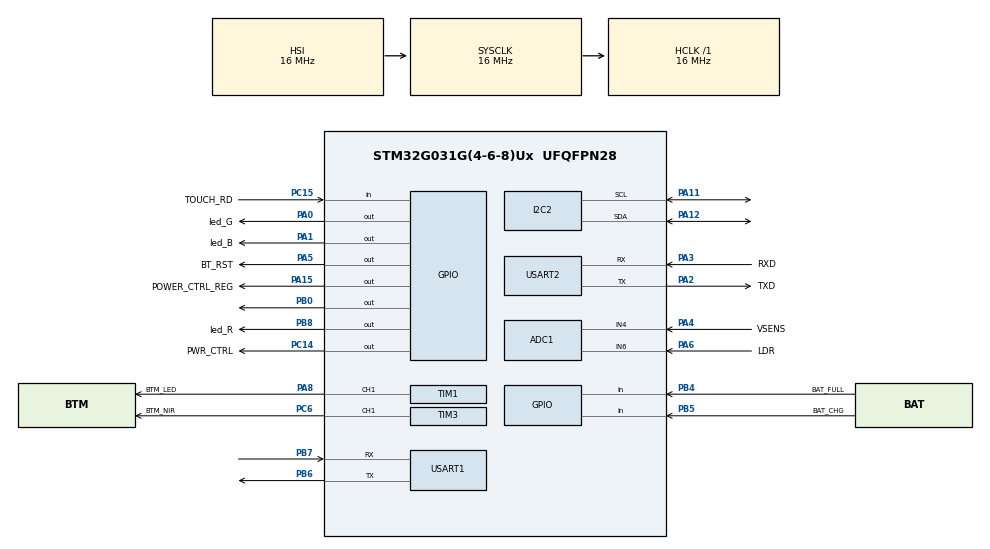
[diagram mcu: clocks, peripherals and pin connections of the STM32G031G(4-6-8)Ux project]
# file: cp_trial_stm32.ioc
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ADC1.Channel-1\#ChannelRegularConversion=ADC_CHANNEL_6
ADC1.NbrOfConversionFlag=1
ADC1.Rank-1\#ChannelRegularConversion=1
ADC1.SamplingTime-1\#ChannelRegularConversion=ADC_SAMPLINGTIME_COMMON_1
ADC1.SelectedChannel=ADC_CHANNEL_4|ADC_CHANNEL_6
ADC1.master=1
I2C2.Timing=0x00503D58
Mcu.Family=STM32G0
Mcu.Name=STM32G031G(4-6-8)Ux
Mcu.Package=UFQFPN28
NVIC.USART2_IRQn=true\:0\:0\:false\:false\:true\:true\:true\:true
PA0.GPIO_Label=led_G
PA0.PinState=GPIO_PIN_SET
PA0.Signal=GPIO_Output
PA1.GPIO_Label=led_B
PA1.PinState=GPIO_PIN_SET
PA1.Signal=GPIO_Output
PA11\ [PA9].Mode=I2C
PA11\ [PA9].Signal=I2C2_SCL
PA12\ [PA10].Mode=I2C
PA12\ [PA10].Signal=I2C2_SDA
PA13.Mode=Serial_Wire
PA13.Signal=SYS_SWDIO
PA14-BOOT0.Mode=Serial_Wire
PA14-BOOT0.Signal=SYS_SWCLK
PA15.GPIO_Label=POWER_CTRL_REG
PA15.PinState=GPIO_PIN_RESET
PA15.Signal=GPIO_Output
PA2.GPIO_Label=TXD
PA2.Mode=Asynchronous
PA2.Signal=USART2_TX
PA3.GPIO_Label=RXD
PA3.Mode=Asynchronous
PA3.Signal=USART2_RX
PA4.GPIO_Label=VSENS
PA4.Mode=IN4
PA4.Signal=ADC1_IN4
PA5.GPIO_Label=BT_RST
PA5.PinState=GPIO_PIN_SET
PA5.Signal=GPIO_Output
PA6.GPIO_Label=LDR
PA6.Mode=IN6
PA6.Signal=ADC1_IN6
PA8.GPIO_Label=BTM_LED
PA8.Signal=S_TIM1_CH1
PB0.PinState=GPIO_PIN_SET
PB0.Signal=GPIO_Output
PB4.GPIO_Label=BAT_FULL
PB4.Signal=GPIO_Input
PB5.GPIO_Label=BAT_CHG
PB5.Signal=GPIO_Input
PB6.Mode=Asynchronous
PB6.Signal=USART1_TX
PB7.Mode=Asynchronous
PB7.Signal=USART1_RX
PB8.GPIO_Label=led_R
PB8.PinState=GPIO_PIN_SET
PB8.Signal=GPIO_Output
PC14-OSC32_IN\ (PC14).GPIO_Label=PWR_CTRL
PC14-OSC32_IN\ (PC14).Signal=GPIO_Output
PC15-OSC32_OUT\ (PC15).GPIO_Label=TOUCH_RD
PC15-OSC32_OUT\ (PC15).Signal=GPIO_Input
PC6.GPIO_Label=BTM_NIR
PC6.Signal=S_TIM3_CH1
ProjectManager.HeapSize=0x200
ProjectManager.StackSize=0x400
ProjectManager.TargetToolchain=STM32CubeIDE
RCC.ADCFreq_Value=16000000
RCC.AHBFreq_Value=16000000
RCC.CortexFreq_Value=16000000
RCC.EXTERNAL_CLOCK_VALUE=12288000
RCC.HCLKFreq_Value=16000000
RCC.HSE_VALUE=8000000
RCC.HSI_VALUE=16000000
RCC.LSE_VALUE=32768
RCC.PLLQ=RCC_PLLQ_DIV4
RCC.SYSCLKFreq_VALUE=16000000
RCC.VCOOutputFreq_Value=128000000
SH.S_TIM1_CH1.0=TIM1_CH1,PWM Generation1 CH1
SH.S_TIM3_CH1.0=TIM3_CH1,PWM Generation1 CH1
TIM1.Channel-PWM\ Generation1\ CH1=TIM_CHANNEL_1
TIM1.Period=99
TIM1.Prescaler=15
TIM3.Channel-PWM\ Generation1\ CH1=TIM_CHANNEL_1
TIM3.Period=999
TIM3.Prescaler=63
USART1.VirtualMode-Asynchronous=VM_ASYNC
USART2.VirtualMode-Asynchronous=VM_ASYNC
VP_TIM1_VS_ClockSourceINT.Mode=Internal
board=custom

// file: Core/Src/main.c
/* USER CODE BEGIN Header */
/**
  ******************************************************************************
  * @file           : main.c
  * @brief          : Main program body
  ******************************************************************************
  * @attention
  *
  * Copyright (c) 2025 STMicroelectronics.
  * All rights reserved.
  *
  * This software is licensed under terms that can be found in the LICENSE file
  * in the root directory of this software component.
  * If no LICENSE file comes with this software, it is provided AS-IS.
  *
  ******************************************************************************
  */
/* USER CODE END Header */
#include "main.h"

/* USER CODE BEGIN Includes */

#include "touch.h"
#include "ble_protocol.h"
#include "routines.h"
#include "flash.h"

/* USER CODE END Includes */

ADC_HandleTypeDef hadc1;

I2C_HandleTypeDef hi2c2;

TIM_HandleTypeDef htim1;
TIM_HandleTypeDef htim3;

UART_HandleTypeDef huart1;
UART_HandleTypeDef huart2;

void SystemClock_Config(void);
static void MX_GPIO_Init(void);
static void MX_ADC1_Init(void);
static void MX_TIM1_Init(void);
static void MX_TIM3_Init(void);
static void MX_USART2_UART_Init(void);
static void MX_I2C2_Init(void);
static void MX_USART1_UART_Init(void);

int main(void)
{

  /* MCU Configuration--------------------------------------------------------*/

  /* Reset of all peripherals, Initializes the Flash interface and the Systick. */
  HAL_Init();

  /* USER CODE BEGIN Init */
  Flash_Init();
  /* USER CODE END Init */

  /* Configure the system clock */
  SystemClock_Config();

  /* Initialize all configured peripherals */
  MX_GPIO_Init();
  MX_ADC1_Init();
  MX_TIM1_Init();
  MX_TIM3_Init();
  MX_USART2_UART_Init();
  MX_I2C2_Init();
  MX_USART1_UART_Init();
  /* USER CODE BEGIN 2 */
  //HAL_GPIO_WritePin(GPIOC, PWR_CTRL_Pin, GPIO_PIN_SET);

  HAL_UART_Receive_IT(&huart2, &rx_byte, 1);
  power_on();

  start_routine();

  session_end();
  clinical_mode_check();
  //Set_Color("red");
  /* USER CODE END 2

  /* Infinite loop */
  /* USER CODE BEGIN WHILE */

  while (1){

	  	  check_dev_charging();
		  process_UART();
		  frame_count_check();
		  touch();
		  session_state();

    /* USER CODE END WHILE */

  }
}

void SystemClock_Config(void)
{
  RCC_OscInitTypeDef RCC_OscInitStruct = {0};
  RCC_ClkInitTypeDef RCC_ClkInitStruct = {0};

  /** Configure the main internal regulator output voltage
  */
  HAL_PWREx_ControlVoltageScaling(PWR_REGULATOR_VOLTAGE_SCALE1);

  /** Initializes the RCC Oscillators according to the specified parameters
  * in the RCC_OscInitTypeDef structure.
  */
  RCC_OscInitStruct.OscillatorType = RCC_OSCILLATORTYPE_HSI;
  RCC_OscInitStruct.HSIState = RCC_HSI_ON;
  RCC_OscInitStruct.HSIDiv = RCC_HSI_DIV1;
  RCC_OscInitStruct.HSICalibrationValue = RCC_HSICALIBRATION_DEFAULT;
  RCC_OscInitStruct.PLL.PLLState = RCC_PLL_NONE;
  if (HAL_RCC_OscConfig(&RCC_OscInitStruct) != HAL_OK)
  {
    Error_Handler();
  }

  /** Initializes the CPU, AHB and APB buses clocks
  */
  RCC_ClkInitStruct.ClockType = RCC_CLOCKTYPE_HCLK|RCC_CLOCKTYPE_SYSCLK
                              |RCC_CLOCKTYPE_PCLK1;
  RCC_ClkInitStruct.SYSCLKSource = RCC_SYSCLKSOURCE_HSI;
  RCC_ClkInitStruct.AHBCLKDivider = RCC_SYSCLK_DIV1;
  RCC_ClkInitStruct.APB1CLKDivider = RCC_HCLK_DIV1;

  if (HAL_RCC_ClockConfig(&RCC_ClkInitStruct, FLASH_LATENCY_0) != HAL_OK)
  {
    Error_Handler();
  }
}

static void MX_ADC1_Init(void)
{

  ADC_ChannelConfTypeDef sConfig = {0};

  /** Configure the global features of the ADC (Clock, Resolution, Data Alignment and number of conversion)
  */
  hadc1.Instance = ADC1;
  hadc1.Init.ClockPrescaler = ADC_CLOCK_SYNC_PCLK_DIV2;
  hadc1.Init.Resolution = ADC_RESOLUTION_12B;
  hadc1.Init.DataAlign = ADC_DATAALIGN_RIGHT;
  hadc1.Init.ScanConvMode = ADC_SCAN_DISABLE;
  hadc1.Init.EOCSelection = ADC_EOC_SINGLE_CONV;
  hadc1.Init.LowPowerAutoWait = DISABLE;
  hadc1.Init.LowPowerAutoPowerOff = DISABLE;
  hadc1.Init.ContinuousConvMode = DISABLE;
  hadc1.Init.NbrOfConversion = 1;
  hadc1.Init.DiscontinuousConvMode = DISABLE;
  hadc1.Init.ExternalTrigConv = ADC_SOFTWARE_START;
  hadc1.Init.ExternalTrigConvEdge = ADC_EXTERNALTRIGCONVEDGE_NONE;
  hadc1.Init.DMAContinuousRequests = DISABLE;
  hadc1.Init.Overrun = ADC_OVR_DATA_PRESERVED;
  hadc1.Init.SamplingTimeCommon1 = ADC_SAMPLETIME_1CYCLE_5;
  hadc1.Init.SamplingTimeCommon2 = ADC_SAMPLETIME_1CYCLE_5;
  hadc1.Init.OversamplingMode = DISABLE;
  hadc1.Init.TriggerFrequencyMode = ADC_TRIGGER_FREQ_HIGH;
  if (HAL_ADC_Init(&hadc1) != HAL_OK)
  {
    Error_Handler();
  }

  /** Configure Regular Channel
  */
  sConfig.Channel = ADC_CHANNEL_6;
  sConfig.Rank = ADC_REGULAR_RANK_1;
  sConfig.SamplingTime = ADC_SAMPLINGTIME_COMMON_1;
  if (HAL_ADC_ConfigChannel(&hadc1, &sConfig) != HAL_OK)
  {
    Error_Handler();
  }

}

static void MX_I2C2_Init(void)
{

  hi2c2.Instance = I2C2;
  hi2c2.Init.Timing = 0x00503D58;
  hi2c2.Init.OwnAddress1 = 0;
  hi2c2.Init.AddressingMode = I2C_ADDRESSINGMODE_7BIT;
  hi2c2.Init.DualAddressMode = I2C_DUALADDRESS_DISABLE;
  hi2c2.Init.OwnAddress2 = 0;
  hi2c2.Init.OwnAddress2Masks = I2C_OA2_NOMASK;
  hi2c2.Init.GeneralCallMode = I2C_GENERALCALL_DISABLE;
  hi2c2.Init.NoStretchMode = I2C_NOSTRETCH_DISABLE;
  if (HAL_I2C_Init(&hi2c2) != HAL_OK)
  {
    Error_Handler();
  }

  /** Configure Analogue filter
  */
  if (HAL_I2CEx_ConfigAnalogFilter(&hi2c2, I2C_ANALOGFILTER_ENABLE) != HAL_OK)
  {
    Error_Handler();
  }

  /** Configure Digital filter
  */
  if (HAL_I2CEx_ConfigDigitalFilter(&hi2c2, 0) != HAL_OK)
  {
    Error_Handler();
  }

}

static void MX_TIM1_Init(void)
{

  TIM_ClockConfigTypeDef sClockSourceConfig = {0};
  TIM_MasterConfigTypeDef sMasterConfig = {0};
  TIM_OC_InitTypeDef sConfigOC = {0};
  TIM_BreakDeadTimeConfigTypeDef sBreakDeadTimeConfig = {0};

  htim1.Instance = TIM1;
  htim1.Init.Prescaler = 15;
  htim1.Init.CounterMode = TIM_COUNTERMODE_UP;
  htim1.Init.Period = 99;
  htim1.Init.ClockDivision = TIM_CLOCKDIVISION_DIV1;
  htim1.Init.RepetitionCounter = 0;
  htim1.Init.AutoReloadPreload = TIM_AUTORELOAD_PRELOAD_DISABLE;
  if (HAL_TIM_Base_Init(&htim1) != HAL_OK)
  {
    Error_Handler();
  }
  sClockSourceConfig.ClockSource = TIM_CLOCKSOURCE_INTERNAL;
  if (HAL_TIM_ConfigClockSource(&htim1, &sClockSourceConfig) != HAL_OK)
  {
    Error_Handler();
  }
  if (HAL_TIM_PWM_Init(&htim1) != HAL_OK)
  {
    Error_Handler();
  }
  sMasterConfig.MasterOutputTrigger = TIM_TRGO_RESET;
  sMasterConfig.MasterOutputTrigger2 = TIM_TRGO2_RESET;
  sMasterConfig.MasterSlaveMode = TIM_MASTERSLAVEMODE_DISABLE;
  if (HAL_TIMEx_MasterConfigSynchronization(&htim1, &sMasterConfig) != HAL_OK)
  {
    Error_Handler();
  }
  sConfigOC.OCMode = TIM_OCMODE_PWM1;
  sConfigOC.Pulse = 0;
  sConfigOC.OCPolarity = TIM_OCPOLARITY_HIGH;
  sConfigOC.OCNPolarity = TIM_OCNPOLARITY_HIGH;
  sConfigOC.OCFastMode = TIM_OCFAST_DISABLE;
  sConfigOC.OCIdleState = TIM_OCIDLESTATE_RESET;
  sConfigOC.OCNIdleState = TIM_OCNIDLESTATE_RESET;
  if (HAL_TIM_PWM_ConfigChannel(&htim1, &sConfigOC, TIM_CHANNEL_1) != HAL_OK)
  {
    Error_Handler();
  }
  sBreakDeadTimeConfig.OffStateRunMode = TIM_OSSR_DISABLE;
  sBreakDeadTimeConfig.OffStateIDLEMode = TIM_OSSI_DISABLE;
  sBreakDeadTimeConfig.LockLevel = TIM_LOCKLEVEL_OFF;
  sBreakDeadTimeConfig.DeadTime = 0;
  sBreakDeadTimeConfig.BreakState = TIM_BREAK_DISABLE;
  sBreakDeadTimeConfig.BreakPolarity = TIM_BREAKPOLARITY_HIGH;
  sBreakDeadTimeConfig.BreakFilter = 0;
  sBreakDeadTimeConfig.BreakAFMode = TIM_BREAK_AFMODE_INPUT;
  sBreakDeadTimeConfig.Break2State = TIM_BREAK2_DISABLE;
  sBreakDeadTimeConfig.Break2Polarity = TIM_BREAK2POLARITY_HIGH;
  sBreakDeadTimeConfig.Break2Filter = 0;
  sBreakDeadTimeConfig.Break2AFMode = TIM_BREAK_AFMODE_INPUT;
  sBreakDeadTimeConfig.AutomaticOutput = TIM_AUTOMATICOUTPUT_DISABLE;
  if (HAL_TIMEx_ConfigBreakDeadTime(&htim1, &sBreakDeadTimeConfig) != HAL_OK)
  {
    Error_Handler();
  }
  HAL_TIM_MspPostInit(&htim1);

}

static void MX_TIM3_Init(void)
{

  TIM_MasterConfigTypeDef sMasterConfig = {0};
  TIM_OC_InitTypeDef sConfigOC = {0};

  htim3.Instance = TIM3;
  htim3.Init.Prescaler = 63;
  htim3.Init.CounterMode = TIM_COUNTERMODE_UP;
  htim3.Init.Period = 999;
  htim3.Init.ClockDivision = TIM_CLOCKDIVISION_DIV1;
  htim3.Init.AutoReloadPreload = TIM_AUTORELOAD_PRELOAD_DISABLE;
  if (HAL_TIM_PWM_Init(&htim3) != HAL_OK)
  {
    Error_Handler();
  }
  sMasterConfig.MasterOutputTrigger = TIM_TRGO_RESET;
  sMasterConfig.MasterSlaveMode = TIM_MASTERSLAVEMODE_DISABLE;
  if (HAL_TIMEx_MasterConfigSynchronization(&htim3, &sMasterConfig) != HAL_OK)
  {
    Error_Handler();
  }
  sConfigOC.OCMode = TIM_OCMODE_PWM1;
  sConfigOC.Pulse = 0;
  sConfigOC.OCPolarity = TIM_OCPOLARITY_HIGH;
  sConfigOC.OCFastMode = TIM_OCFAST_DISABLE;
  if (HAL_TIM_PWM_ConfigChannel(&htim3, &sConfigOC, TIM_CHANNEL_1) != HAL_OK)
  {
    Error_Handler();
  }
  HAL_TIM_MspPostInit(&htim3);

}

static void MX_USART1_UART_Init(void)
{

  huart1.Instance = USART1;
  huart1.Init.BaudRate = 115200;
  huart1.Init.WordLength = UART_WORDLENGTH_8B;
  huart1.Init.StopBits = UART_STOPBITS_1;
  huart1.Init.Parity = UART_PARITY_NONE;
  huart1.Init.Mode = UART_MODE_TX_RX;
  huart1.Init.HwFlowCtl = UART_HWCONTROL_NONE;
  huart1.Init.OverSampling = UART_OVERSAMPLING_16;
  huart1.Init.OneBitSampling = UART_ONE_BIT_SAMPLE_DISABLE;
  huart1.Init.ClockPrescaler = UART_PRESCALER_DIV1;
  huart1.AdvancedInit.AdvFeatureInit = UART_ADVFEATURE_NO_INIT;
  if (HAL_UART_Init(&huart1) != HAL_OK)
  {
    Error_Handler();
  }
  if (HAL_UARTEx_SetTxFifoThreshold(&huart1, UART_TXFIFO_THRESHOLD_1_8) != HAL_OK)
  {
    Error_Handler();
  }
  if (HAL_UARTEx_SetRxFifoThreshold(&huart1, UART_RXFIFO_THRESHOLD_1_8) != HAL_OK)
  {
    Error_Handler();
  }
  if (HAL_UARTEx_DisableFifoMode(&huart1) != HAL_OK)
  {
    Error_Handler();
  }

}

static void MX_USART2_UART_Init(void)
{

  huart2.Instance = USART2;
  huart2.Init.BaudRate = 115200;
  huart2.Init.WordLength = UART_WORDLENGTH_8B;
  huart2.Init.StopBits = UART_STOPBITS_1;
  huart2.Init.Parity = UART_PARITY_NONE;
  huart2.Init.Mode = UART_MODE_TX_RX;
  huart2.Init.HwFlowCtl = UART_HWCONTROL_NONE;
  huart2.Init.OverSampling = UART_OVERSAMPLING_16;
  huart2.Init.OneBitSampling = UART_ONE_BIT_SAMPLE_DISABLE;
  huart2.Init.ClockPrescaler = UART_PRESCALER_DIV1;
  huart2.AdvancedInit.AdvFeatureInit = UART_ADVFEATURE_NO_INIT;
  if (HAL_UART_Init(&huart2) != HAL_OK)
  {
    Error_Handler();
  }

}

static void MX_GPIO_Init(void)
{
  GPIO_InitTypeDef GPIO_InitStruct = {0};

  /* GPIO Ports Clock Enable */
  __HAL_RCC_GPIOC_CLK_ENABLE();
  __HAL_RCC_GPIOA_CLK_ENABLE();
  __HAL_RCC_GPIOB_CLK_ENABLE();

  /*Configure GPIO pin Output Level */
  HAL_GPIO_WritePin(PWR_CTRL_GPIO_Port, PWR_CTRL_Pin, GPIO_PIN_RESET);

  /*Configure GPIO pin Output Level */
  HAL_GPIO_WritePin(GPIOA, led_G_Pin|led_B_Pin|BT_RST_Pin, GPIO_PIN_SET);

  /*Configure GPIO pin Output Level */
  HAL_GPIO_WritePin(GPIOB, GPIO_PIN_0|led_R_Pin, GPIO_PIN_SET);

  /*Configure GPIO pin Output Level */
  HAL_GPIO_WritePin(POWER_CTRL_REG_GPIO_Port, POWER_CTRL_REG_Pin, GPIO_PIN_RESET);

  /*Configure GPIO pin : PWR_CTRL_Pin */
  GPIO_InitStruct.Pin = PWR_CTRL_Pin;
  GPIO_InitStruct.Mode = GPIO_MODE_OUTPUT_PP;
  GPIO_InitStruct.Pull = GPIO_NOPULL;
  GPIO_InitStruct.Speed = GPIO_SPEED_FREQ_LOW;
  HAL_GPIO_Init(PWR_CTRL_GPIO_Port, &GPIO_InitStruct);

  /*Configure GPIO pin : TOUCH_RD_Pin */
  GPIO_InitStruct.Pin = TOUCH_RD_Pin;
  GPIO_InitStruct.Mode = GPIO_MODE_INPUT;
  GPIO_InitStruct.Pull = GPIO_NOPULL;
  HAL_GPIO_Init(TOUCH_RD_GPIO_Port, &GPIO_InitStruct);

  /*Configure GPIO pins : led_G_Pin led_B_Pin BT_RST_Pin POWER_CTRL_REG_Pin */
  GPIO_InitStruct.Pin = led_G_Pin|led_B_Pin|BT_RST_Pin|POWER_CTRL_REG_Pin;
  GPIO_InitStruct.Mode = GPIO_MODE_OUTPUT_PP;
  GPIO_InitStruct.Pull = GPIO_NOPULL;
  GPIO_InitStruct.Speed = GPIO_SPEED_FREQ_LOW;
  HAL_GPIO_Init(GPIOA, &GPIO_InitStruct);

  /*Configure GPIO pins : PB0 led_R_Pin */
  GPIO_InitStruct.Pin = GPIO_PIN_0|led_R_Pin;
  GPIO_InitStruct.Mode = GPIO_MODE_OUTPUT_PP;
  GPIO_InitStruct.Pull = GPIO_NOPULL;
  GPIO_InitStruct.Speed = GPIO_SPEED_FREQ_LOW;
  HAL_GPIO_Init(GPIOB, &GPIO_InitStruct);

  /*Configure GPIO pins : BAT_FULL_Pin BAT_CHG_Pin */
  GPIO_InitStruct.Pin = BAT_FULL_Pin|BAT_CHG_Pin;
  GPIO_InitStruct.Mode = GPIO_MODE_INPUT;
  GPIO_InitStruct.Pull = GPIO_NOPULL;
  HAL_GPIO_Init(GPIOB, &GPIO_InitStruct);

}

void Error_Handler(void)
{
  __disable_irq();
  while (1)
  {
  }
}
